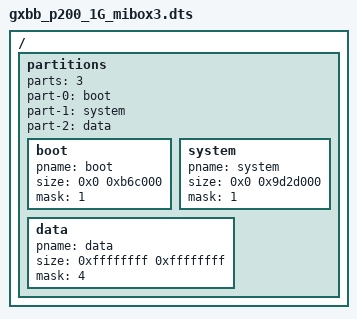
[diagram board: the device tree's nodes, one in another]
/*
 * Amlogic Ltd. GXBaby Plaform
 *
 */

/dts-v1/;

#include "gxbb_p200_1G_mibox3.dtsi"
/ {
		partitions: partitions{
			parts = <3>;
			part-0 = <&boot>;
			part-1 = <&system>;
			part-2 = <&data>;
			boot:boot{
					pname = "boot";
					size = <0x0 0xb6c000>;
					mask = <1>;
			};
			system:system{
					pname = "system";
					size = <0x0 0x9d2d000>;
					mask = <1>;
			};
			data:data
			{
					pname = "data";
					size = <0xffffffff 0xffffffff>;
					mask = <4>;
			};
	};
};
